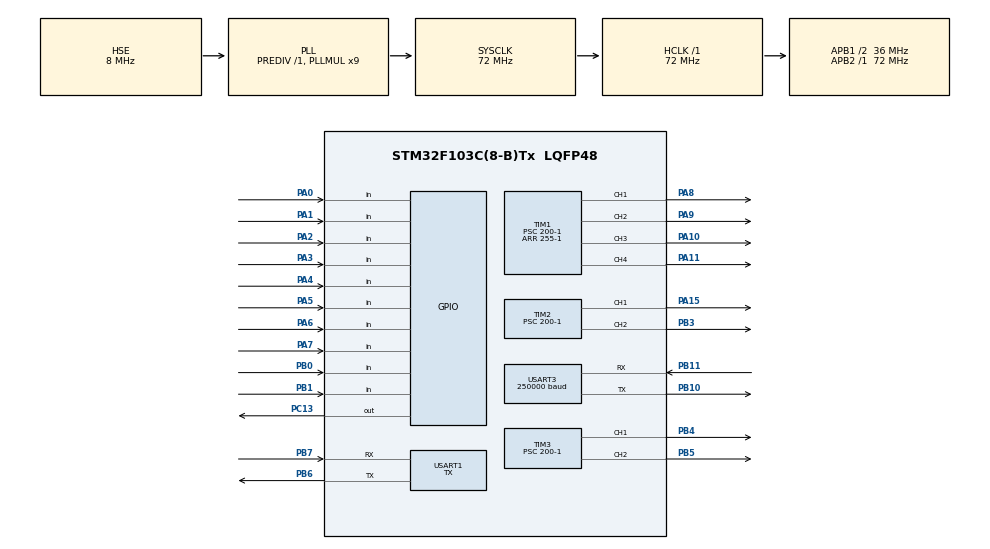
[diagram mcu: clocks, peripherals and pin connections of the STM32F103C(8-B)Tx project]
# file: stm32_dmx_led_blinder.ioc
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Dma.Request0=USART3_RX
Dma.USART3_RX.0.Direction=DMA_PERIPH_TO_MEMORY
Dma.USART3_RX.0.Instance=DMA1_Channel3
Dma.USART3_RX.0.MemDataAlignment=DMA_MDATAALIGN_BYTE
Dma.USART3_RX.0.MemInc=DMA_MINC_ENABLE
Dma.USART3_RX.0.Mode=DMA_NORMAL
Dma.USART3_RX.0.PeriphDataAlignment=DMA_PDATAALIGN_BYTE
Dma.USART3_RX.0.PeriphInc=DMA_PINC_DISABLE
Dma.USART3_RX.0.Priority=DMA_PRIORITY_MEDIUM
Mcu.Family=STM32F1
Mcu.Name=STM32F103C(8-B)Tx
Mcu.Package=LQFP48
NVIC.DMA1_Channel3_IRQn=true\:0\:0\:false\:false\:true\:false\:true
NVIC.PriorityGroup=NVIC_PRIORITYGROUP_4
NVIC.USART3_IRQn=true\:0\:0\:false\:false\:true\:true\:true
PA0-WKUP.GPIO_PuPd=GPIO_PULLDOWN
PA0-WKUP.Signal=GPIO_Input
PA1.GPIO_PuPd=GPIO_PULLDOWN
PA1.Signal=GPIO_Input
PA10.Signal=S_TIM1_CH3
PA11.Signal=S_TIM1_CH4
PA13.Mode=Serial_Wire
PA13.Signal=SYS_JTMS-SWDIO
PA14.Mode=Serial_Wire
PA14.Signal=SYS_JTCK-SWCLK
PA15.Signal=S_TIM2_CH1_ETR
PA2.GPIO_PuPd=GPIO_PULLDOWN
PA2.Signal=GPIO_Input
PA3.GPIO_PuPd=GPIO_PULLDOWN
PA3.Signal=GPIO_Input
PA4.GPIO_PuPd=GPIO_PULLDOWN
PA4.Signal=GPIO_Input
PA5.GPIO_PuPd=GPIO_PULLDOWN
PA5.Signal=GPIO_Input
PA6.GPIO_PuPd=GPIO_PULLDOWN
PA6.Signal=GPIO_Input
PA7.GPIO_PuPd=GPIO_PULLDOWN
PA7.Signal=GPIO_Input
PA8.Signal=S_TIM1_CH1
PA9.Signal=S_TIM1_CH2
PB0.GPIO_PuPd=GPIO_PULLDOWN
PB0.Signal=GPIO_Input
PB1.GPIO_PuPd=GPIO_PULLDOWN
PB1.Signal=GPIO_Input
PB10.Mode=Asynchronous
PB10.Signal=USART3_TX
PB11.Mode=Asynchronous
PB11.Signal=USART3_RX
PB3.Signal=S_TIM2_CH2
PB4.Signal=S_TIM3_CH1
PB5.Signal=S_TIM3_CH2
PB6.Mode=Asynchronous
PB6.Signal=USART1_TX
PB7.Mode=Asynchronous
PB7.Signal=USART1_RX
PC13-TAMPER-RTC.Signal=GPIO_Output
PD0-OSC_IN.Mode=HSE-External-Oscillator
PD0-OSC_IN.Signal=RCC_OSC_IN
PD1-OSC_OUT.Mode=HSE-External-Oscillator
PD1-OSC_OUT.Signal=RCC_OSC_OUT
ProjectManager.HeapSize=0x200
ProjectManager.StackSize=0x400
ProjectManager.TargetToolchain=STM32CubeIDE
RCC.ADCPresc=RCC_ADCPCLK2_DIV6
RCC.AHBFreq_Value=72000000
RCC.APB1CLKDivider=RCC_HCLK_DIV2
RCC.APB1Freq_Value=36000000
RCC.APB1TimFreq_Value=72000000
RCC.APB2Freq_Value=72000000
RCC.APB2TimFreq_Value=72000000
RCC.EnbaleCSS=true
RCC.HCLKFreq_Value=72000000
RCC.PLLMUL=RCC_PLL_MUL9
RCC.PLLSourceVirtual=RCC_PLLSOURCE_HSE
RCC.SYSCLKFreq_VALUE=72000000
RCC.SYSCLKSource=RCC_SYSCLKSOURCE_PLLCLK
RCC.USBFreq_Value=72000000
SH.S_TIM1_CH1.0=TIM1_CH1,PWM Generation1 CH1
SH.S_TIM1_CH2.0=TIM1_CH2,PWM Generation2 CH2
SH.S_TIM1_CH3.0=TIM1_CH3,PWM Generation3 CH3
SH.S_TIM1_CH4.0=TIM1_CH4,PWM Generation4 CH4
SH.S_TIM2_CH1_ETR.0=TIM2_CH1,PWM Generation1 CH1
SH.S_TIM2_CH2.0=TIM2_CH2,PWM Generation2 CH2
SH.S_TIM3_CH1.0=TIM3_CH1,PWM Generation1 CH1
SH.S_TIM3_CH2.0=TIM3_CH2,PWM Generation2 CH2
TIM1.Channel-PWM\ Generation1\ CH1=TIM_CHANNEL_1
TIM1.Channel-PWM\ Generation2\ CH2=TIM_CHANNEL_2
TIM1.Channel-PWM\ Generation3\ CH3=TIM_CHANNEL_3
TIM1.Channel-PWM\ Generation4\ CH4=TIM_CHANNEL_4
TIM1.Period=255-1
TIM1.Prescaler=200-1
TIM2.Channel-PWM\ Generation1\ CH1=TIM_CHANNEL_1
TIM2.Channel-PWM\ Generation2\ CH2=TIM_CHANNEL_2
TIM2.OCFastMode_PWM-PWM\ Generation1\ CH1=TIM_OCFAST_DISABLE
TIM2.OCFastMode_PWM-PWM\ Generation2\ CH2=TIM_OCFAST_DISABLE
TIM2.Period=255-1
TIM2.Prescaler=200-1
TIM3.Channel-PWM\ Generation1\ CH1=TIM_CHANNEL_1
TIM3.Channel-PWM\ Generation2\ CH2=TIM_CHANNEL_2
TIM3.Period=255-1
TIM3.Prescaler=200-1
USART1.Mode=MODE_TX
USART1.VirtualMode=VM_ASYNC
USART3.BaudRate=250000
USART3.StopBits=STOPBITS_2
USART3.VirtualMode=VM_ASYNC
board=custom

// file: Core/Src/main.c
/* USER CODE BEGIN Header */
/**
  ******************************************************************************
  * @file           : main.c
  * @brief          : Main program body
  ******************************************************************************
  * @attention
  *
  * <h2><center>&copy; Copyright (c) 2020 STMicroelectronics.
  * All rights reserved.</center></h2>
  *
  * This software component is licensed by ST under BSD 3-Clause license,
  * the "License"; You may not use this file except in compliance with the
  * License. You may obtain a copy of the License at:
  *                        opensource.org/licenses/BSD-3-Clause
  *
  ******************************************************************************
  */
/* USER CODE END Header */

#include "main.h"
#include "dma.h"
#include "tim.h"
#include "usart.h"
#include "gpio.h"

/* USER CODE BEGIN Includes */
#include "UsrSrc/main.hpp"
/* USER CODE END Includes */

void SystemClock_Config(void);

int main(void)
{

  /* MCU Configuration--------------------------------------------------------*/

  /* Reset of all peripherals, Initializes the Flash interface and the Systick. */
  HAL_Init();

  /* Configure the system clock */
  SystemClock_Config();

  /* Initialize all configured peripherals */
  MX_GPIO_Init();
  MX_DMA_Init();
  MX_USART1_UART_Init();
  MX_USART3_UART_Init();
  MX_TIM1_Init();
  MX_TIM2_Init();
  MX_TIM3_Init();
  /* USER CODE BEGIN 2 */
  init();
  /* USER CODE END 2 */

  /* Infinite loop */
  /* USER CODE BEGIN WHILE */
  while (1)
  {
	  loop();
    /* USER CODE END WHILE */

  }
}

void SystemClock_Config(void)
{
  RCC_OscInitTypeDef RCC_OscInitStruct = {0};
  RCC_ClkInitTypeDef RCC_ClkInitStruct = {0};

  /** Initializes the CPU, AHB and APB busses clocks
  */
  RCC_OscInitStruct.OscillatorType = RCC_OSCILLATORTYPE_HSE;
  RCC_OscInitStruct.HSEState = RCC_HSE_ON;
  RCC_OscInitStruct.HSEPredivValue = RCC_HSE_PREDIV_DIV1;
  RCC_OscInitStruct.HSIState = RCC_HSI_ON;
  RCC_OscInitStruct.PLL.PLLState = RCC_PLL_ON;
  RCC_OscInitStruct.PLL.PLLSource = RCC_PLLSOURCE_HSE;
  RCC_OscInitStruct.PLL.PLLMUL = RCC_PLL_MUL9;
  if (HAL_RCC_OscConfig(&RCC_OscInitStruct) != HAL_OK)
  {
    Error_Handler();
  }
  /** Initializes the CPU, AHB and APB busses clocks
  */
  RCC_ClkInitStruct.ClockType = RCC_CLOCKTYPE_HCLK|RCC_CLOCKTYPE_SYSCLK
                              |RCC_CLOCKTYPE_PCLK1|RCC_CLOCKTYPE_PCLK2;
  RCC_ClkInitStruct.SYSCLKSource = RCC_SYSCLKSOURCE_PLLCLK;
  RCC_ClkInitStruct.AHBCLKDivider = RCC_SYSCLK_DIV1;
  RCC_ClkInitStruct.APB1CLKDivider = RCC_HCLK_DIV2;
  RCC_ClkInitStruct.APB2CLKDivider = RCC_HCLK_DIV1;

  if (HAL_RCC_ClockConfig(&RCC_ClkInitStruct, FLASH_LATENCY_2) != HAL_OK)
  {
    Error_Handler();
  }
  /** Enables the Clock Security System
  */
  HAL_RCC_EnableCSS();
}

void Error_Handler(void)
{
}

/************************ (C) COPYRIGHT STMicroelectronics *****END OF FILE****/
